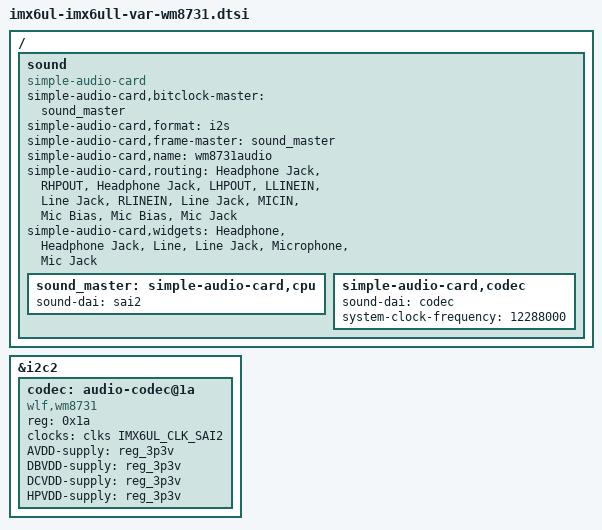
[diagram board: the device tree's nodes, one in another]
// SPDX-License-Identifier: GPL-2.0+
/*
 * Copyright (C) 2026 Variscite Ltd. - https://www.variscite.com
 */

#include "imx6ul-var-som-audio.dtsi"

/ {
	sound {
		compatible = "simple-audio-card";
		simple-audio-card,bitclock-master = <&sound_master>;
		simple-audio-card,format = "i2s";
		simple-audio-card,frame-master = <&sound_master>;
		simple-audio-card,name = "wm8731audio";
		simple-audio-card,routing =
			"Headphone Jack", "RHPOUT",
			"Headphone Jack", "LHPOUT",
			"LLINEIN", "Line Jack",
			"RLINEIN", "Line Jack",
			"MICIN", "Mic Bias",
			"Mic Bias", "Mic Jack";
		simple-audio-card,widgets =
			"Headphone", "Headphone Jack",
			"Line", "Line Jack",
			"Microphone", "Mic Jack";

		sound_master: simple-audio-card,cpu {
			sound-dai = <&sai2>;
		};

		simple-audio-card,codec {
			sound-dai = <&codec>;
			system-clock-frequency = <12288000>;
		};
	};
};

&i2c2 {
	codec: audio-codec@1a {
		compatible = "wlf,wm8731";
		reg = <0x1a>;
		#sound-dai-cells = <0>;
		clocks = <&clks IMX6UL_CLK_SAI2>;
		clock-names = "mclk";
		AVDD-supply = <&reg_3p3v>;
		DBVDD-supply = <&reg_3p3v>;
		DCVDD-supply = <&reg_3p3v>;
		HPVDD-supply = <&reg_3p3v>;
	};
};
